# AM13E23219 register map
Vendor: Texas Instruments; File version: 1.0
CPU: CM33 r0p1, little endian, MPU, FPU, VTOR, 4 interrupt priority bits
Registers are 32-bit, read-write, reset 0x0 unless marked. A register's access mark holds for its fields unless they carry their own. Offsets are from the block's base; [hi:lo] are bit positions; lines under a group give offsets from that group; {n}, {i} and the like mark numbered series; 'fields as' and 'values as' point back to an identical list.

## FSI_TX_A — FSI_TX module
Base 0x40500000
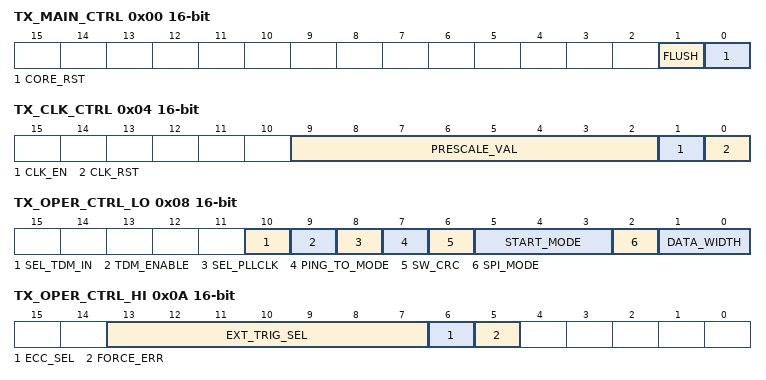
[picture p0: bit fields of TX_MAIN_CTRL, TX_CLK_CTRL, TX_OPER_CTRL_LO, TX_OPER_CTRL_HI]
0x00 TX_MAIN_CTRL 16-bit — Transmit main control register
  [1] FLUSH — Flush Operation Start
  [0] CORE_RST — Transmitter Main Core Reset
0x04 TX_CLK_CTRL 16-bit — Transmit clock control register
  [9:2] PRESCALE_VAL — Prescale value
  [1] CLK_EN — Clock Divider Enable
  [0] CLK_RST — Soft Reset for the Clock Divider
0x08 TX_OPER_CTRL_LO 16-bit — Transmit operation control register low
  [10] SEL_TDM_IN — Input TDM Port Select
  [9] TDM_ENABLE — Transmit TDM Mode Enable
  [8] SEL_PLLCLK — Input Clock Select
  [7] PING_TO_MODE — Ping Counter Reset Mode Select
  [6] SW_CRC — CRC Source Select
  [5:3] START_MODE — Transmission Start Mode Select
  [2] SPI_MODE — SPI Mode Select
  [1:0] DATA_WIDTH — Transmit Data width
0x0A TX_OPER_CTRL_HI 16-bit — Transmit operation control register high
  [13:7] EXT_TRIG_SEL — External Trigger Select
  [6] ECC_SEL — ECC Data Width Select
  [5] FORCE_ERR — Error Frame Force
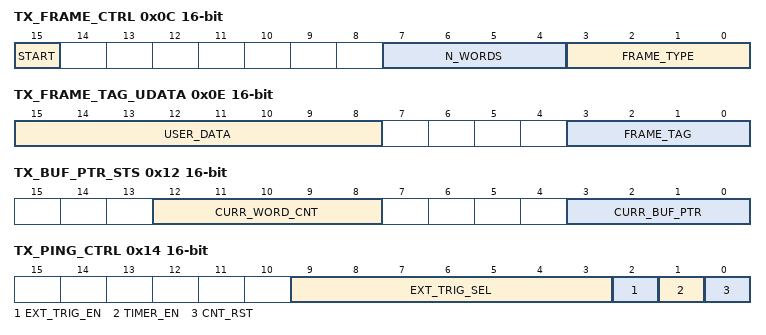
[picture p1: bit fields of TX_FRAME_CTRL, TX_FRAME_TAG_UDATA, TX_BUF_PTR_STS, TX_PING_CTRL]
0x0C TX_FRAME_CTRL 16-bit — Transmit frame control register
  [15] START — Start Transmission
  [7:4] N_WORDS — Number of Words to be Transmitted
  [3:0] FRAME_TYPE — Transmit Frame Type
0x0E TX_FRAME_TAG_UDATA 16-bit — Transmit frame tag and user data register
  [15:8] USER_DATA, [3:0] FRAME_TAG
0x10 TX_BUF_PTR_LOAD 16-bit — Transmit buffer pointer control load register
  [3:0] BUF_PTR_LOAD — Buffer Pointer Force Load
0x12 TX_BUF_PTR_STS 16-bit ro — Transmit buffer pointer control status register
  [12:8] CURR_WORD_CNT — Remaining Words in Buffer
  [3:0] CURR_BUF_PTR — Current Buffer Pointer Index
0x14 TX_PING_CTRL 16-bit — Transmit ping control register
  [9:3] EXT_TRIG_SEL — External Trigger Select
  [2] EXT_TRIG_EN — External Trigger Enable
  [1] TIMER_EN — Ping Counter Enable
  [0] CNT_RST — Ping Counter Reset
0x16 TX_PING_TAG 16-bit — Transmit ping tag register
  [3:0] TAG — Ping Frame Tag
0x18 TX_PING_TO_REF access not given — Transmit ping timeout counter reference
0x1C TX_PING_TO_CNT access not given — Transmit ping timeout current count
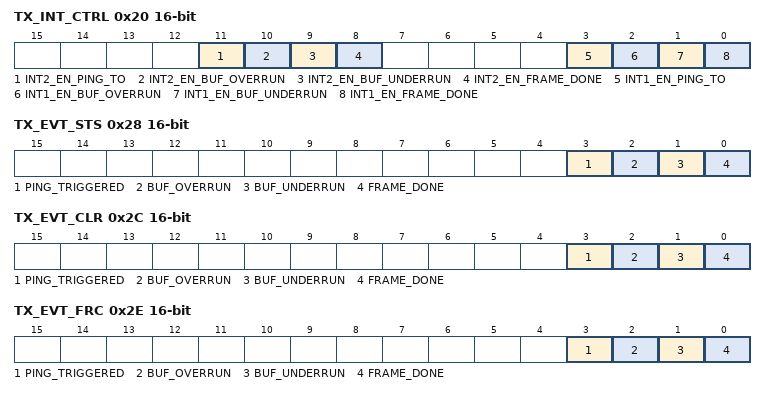
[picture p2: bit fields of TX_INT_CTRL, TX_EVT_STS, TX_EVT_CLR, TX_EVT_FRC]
0x20 TX_INT_CTRL 16-bit — Transmit interrupt event control register
  [11] INT2_EN_PING_TO — Enable Ping Timer Interrupt to INT2
  [10] INT2_EN_BUF_OVERRUN — Enable Buffer Overrun Interrupt to INT2
  [9] INT2_EN_BUF_UNDERRUN — Enable Buffer Underrun Interrupt to INT2
  [8] INT2_EN_FRAME_DONE — Enable Frame Done Interrupt to INT2
  [3] INT1_EN_PING_TO — Enable Ping Timer Interrupt to INT1
  [2] INT1_EN_BUF_OVERRUN — Enable Buffer Overrun Interrupt to INT1
  [1] INT1_EN_BUF_UNDERRUN — Enable Buffer Underrun Interrupt to INT1
  [0] INT1_EN_FRAME_DONE — Enable Frame Done Interrupt to INT1
0x22 TX_DMA_CTRL 16-bit — Transmit DMA event control register
  [0] DMA_EVT_EN — DMA Event Enable
0x24 TX_LOCK_CTRL 16-bit — Transmit lock control register
  [0] LOCK — Control Register Lock Enable
0x28 TX_EVT_STS 16-bit ro — Transmit event and error status flag register
  [3] PING_TRIGGERED — Ping Frame Triggered Flag
  [2] BUF_OVERRUN — Buffer Overrun Flag
  [1] BUF_UNDERRUN — Buffer Underrun Flag
  [0] FRAME_DONE — Frame Done Flag
0x2C TX_EVT_CLR 16-bit — Transmit event and error clear register
  [3] PING_TRIGGERED — Ping Frame Triggered Flag Clear
  [2] BUF_OVERRUN — Buffer Overrun Flag Clear
  [1] BUF_UNDERRUN — Buffer Underrun Flag Clear
  [0] FRAME_DONE — Frame Done Flag Clear
0x2E TX_EVT_FRC 16-bit — Transmit event and error flag force register
  [3] PING_TRIGGERED — Ping Frame Triggered Flag Force
  [2] BUF_OVERRUN — Buffer Overrun Flag Force
  [1] BUF_UNDERRUN — Buffer Underrun Flag Force
  [0] FRAME_DONE — Frame Done Flag Force
0x30 TX_USER_CRC 16-bit — Transmit user-defined CRC register
  [7:0] USER_CRC — User-defined CRC
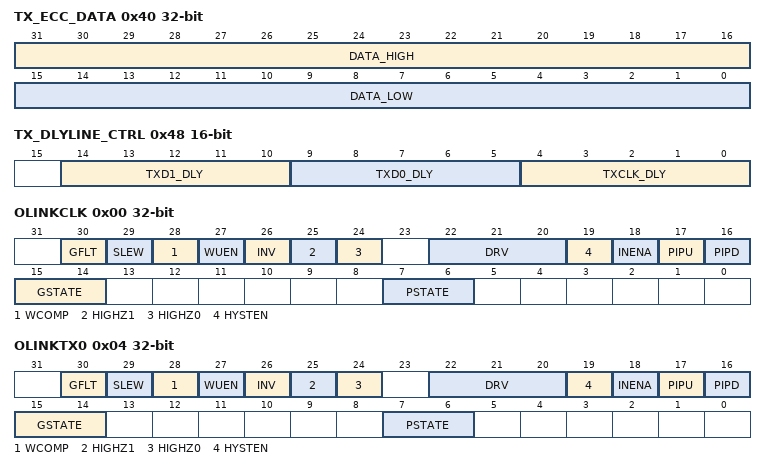
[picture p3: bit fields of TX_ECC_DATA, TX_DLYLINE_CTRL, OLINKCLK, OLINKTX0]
0x40 TX_ECC_DATA — Transmit ECC data register
  [31:16] DATA_HIGH — ECC Data Upper 16 Bits
  [15:0] DATA_LOW — ECC Data Lower 16 Bits
0x44 TX_ECC_VAL 16-bit ro — Transmit ECC value register
  [6:0] ECC_VAL — Computed ECC Value
0x48 TX_DLYLINE_CTRL 16-bit — Transmit delay Line control register
  [14:10] TXD1_DLY — Delay Line Tap Select for TXD1
  [9:5] TXD0_DLY — Delay Line Tap Select for TXD0
  [4:0] TXCLK_DLY — Delay Line Tap Select for TXCLK
{0x80+2i} TX_BUF_BASE[{i}] (i=0..15) 16-bit access not given — Base address for transmit buffer
0x404 PINCM group
  0x00 OLINKCLK — Link clock output for communication interface
    [30] GFLT — Glitch Filter Enable
      0=DISABLE (No internal glitch filter); 1=ENABLE (Use internal glitch filter)
    [29] SLEW — Reserved Slew Rate Control
      0=DISABLE (No Slew Rate Control); 1=ENABLE (Use Slew Rate Control)
    [28] WCOMP — Wake up compare value
      0=MATCH_ZERO (Match 0 will wake); 1=MATCH_ONE (Match 1 will wake)
    [27] WUEN — Wake up enable
      0=NO_WAKEUP (Wake up not enabled); 1=WAKEUP (Wake up enabled)
    [26] INV — Invert digital input/output relative to peripheral/GPIO
      0=NO_CHNG (Input and output are non-inverted); 1=CHNG (Input and output are inverted)
    [25] HIGHZ1 — High-Z instead of high output
      0=DRV_HIGH (Pin can be driven high); 1=DRV_HIZ (Pin is tri-stated instead of driven high)
    [24] HIGHZ0 — High-Z instead of low output
      0=DRV_LOW (Pin can be driven low); 1=DRV_HIZ (Pin is tri-stated instead of driven low)
    [22:20] DRV — Drive strength options
      0=STRENGTH_0 (Lowest drive strength); {v}=STRENGTH_{v} (Drive strength {v+1}/8) (v=1..6); 7=STRENGTH_7 (Highest drive strength)
    [19] HYSTEN — Hysteresis enable
      0=DIS_HYST (No hysteresis); 1=EN_HYST (Hysteresis on)
    [18] INENA — Input enable
      0=INP_DISABLE (Inputs 0 to connected core); 1=INP_ENABLE (Inputs IO pad value to connected core)
    [17] PIPU — Pull up enable
      0=NO_PULL_UP; 1=PULL_UP
    [16] PIPD — Pull down enable
      0=NO_PULL_DOWN; 1=PULL_DOWN
    [15:14] GSTATE — GPIO Channel State
      0=UNASSIGNED (G-Channel is in Unassigned State); 1=HANDOVER (G-Channel is in Handover State); 2=CONC_NOT_LOCKED (G-Channel is in Connected State and not Locked (That is F field is allowed to change without going back through Unassigned state)); 3=CONC_LOCKED (G-Channel is in Connected State and Locked (That is F field is not allowed to change to a different non-Zero value until both G and P channels go to Unassigned))
    [7:6] PSTATE — Peripheral-Analog Channel State
      0=UNASSIGNED (P-Channel is in Unassigned State); 1=HANDOVER (P-Channel is in Handover State); 2=CONC_NOT_LOCKED (P-Channel is in Connected State and not Locked (That is F field is allowed to change without going back through Unassigned state)); 3=CONC_LOCKED (P-Channel is in Connected State and Locked (That is F field is not allowed to change to a different non-Zero value until both G and P channels go to Unassigned))
  0x04 OLINKTX0 — Link transmit 0 output signal going to GPIO mux for external transmission
    fields as PINCM.OLINKCLK
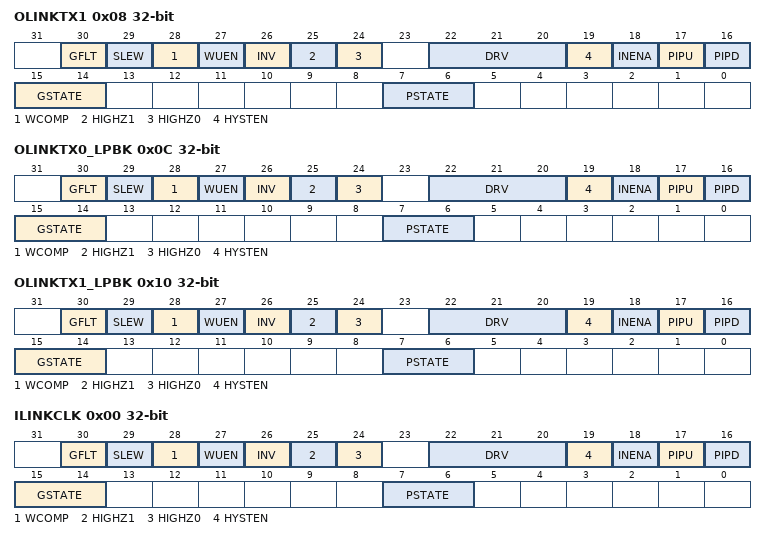
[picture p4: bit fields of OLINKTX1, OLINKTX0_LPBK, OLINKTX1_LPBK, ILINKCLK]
  0x08 OLINKTX1 — Link transmit 1 output signal going to GPIO mux for external transmission
    fields as PINCM.OLINKCLK
  0x0C OLINKTX0_LPBK — Link transmit 0 loopback output signal for external routing through GPIO
    fields as PINCM.OLINKCLK
  0x10 OLINKTX1_LPBK — Link transmit 1 loopback output signal for external routing through GPIO
    fields as PINCM.OLINKCLK
0x604 FUPDATE group
  0x00 OLINKCLK — FUPDATE version of OLINKCLK
    [27:2] IOADDR — IO Address. This is the address that corresponds to the SOC address[27:2] of the module IP instance specific IO signal in the "Full Write" subregion of the pinmux subregion.
    [1] LOCK — Sets lock bit
      0=NOEFFECT (Writing this value has no effect); 1=LOCK (Set channel lock bit)
    [0] GSEL — GPIO channel Select 0: Select the P-Channel for the F update 1: Select the G-Channel for the F update
      0=PCHAN (Select the P-Channel for the F update); 1=GCHAN (Select the G-Channel for the F update)
  0x04 OLINKTX0 — FUPDATE version of OLINKTX0
    fields as FUPDATE.OLINKCLK
  0x08 OLINKTX1 — FUPDATE version of OLINKTX1
    fields as FUPDATE.OLINKCLK
  0x0C OLINKTX0_LPBK — FUPDATE version of OLINKTX0_LPBK
    fields as FUPDATE.OLINKCLK
  0x10 OLINKTX1_LPBK — FUPDATE version of OLINKTX1_LPBK
    fields as FUPDATE.OLINKCLK
  0x804 PINCM group
    0x00 ILINKCLK — Link clock input for FSI receiver link interface timing
      fields as PINCM.OLINKCLK
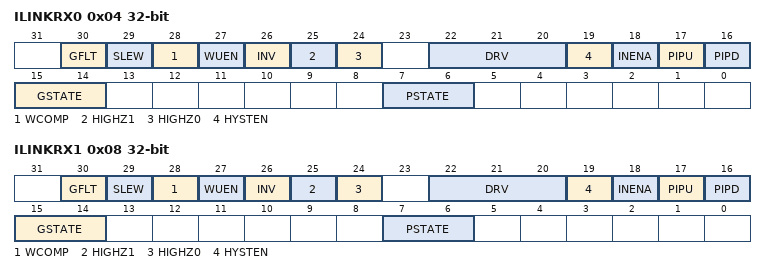
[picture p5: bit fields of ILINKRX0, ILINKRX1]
    0x04 ILINKRX0 — Physical layer link receive channel 0 - single-bit serial interface signal
      fields as PINCM.OLINKCLK
    0x08 ILINKRX1 — Physical layer link receive channel 1 - single-bit serial interface signal
      fields as PINCM.OLINKCLK
  0xA04 FUPDATE group
    0x00 ILINKCLK — FUPDATE version of ILINKCLK
      fields as FUPDATE.OLINKCLK
    0x04 ILINKRX0 — FUPDATE version of ILINKRX0
      fields as FUPDATE.OLINKCLK
    0x08 ILINKRX1 — FUPDATE version of ILINKRX1
      fields as FUPDATE.OLINKCLK
